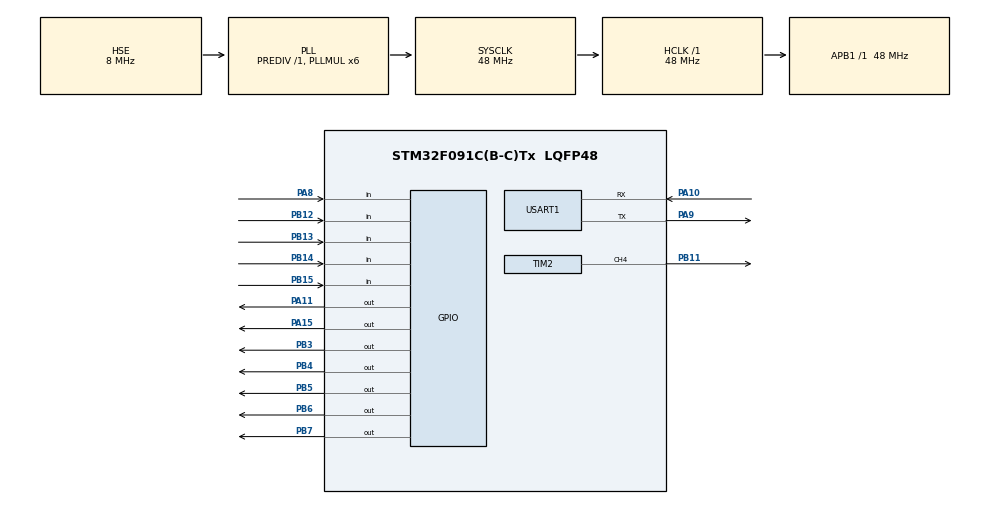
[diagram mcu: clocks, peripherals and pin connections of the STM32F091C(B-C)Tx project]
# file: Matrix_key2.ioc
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Dma.Request0=TIM2_CH4
Dma.TIM2_CH4.0.Direction=DMA_MEMORY_TO_PERIPH
Dma.TIM2_CH4.0.Instance=DMA1_Channel4
Dma.TIM2_CH4.0.MemDataAlignment=DMA_MDATAALIGN_WORD
Dma.TIM2_CH4.0.MemInc=DMA_MINC_ENABLE
Dma.TIM2_CH4.0.Mode=DMA_NORMAL
Dma.TIM2_CH4.0.PeriphDataAlignment=DMA_PDATAALIGN_WORD
Dma.TIM2_CH4.0.PeriphInc=DMA_PINC_DISABLE
Dma.TIM2_CH4.0.Priority=DMA_PRIORITY_LOW
Mcu.Family=STM32F0
Mcu.Name=STM32F091C(B-C)Tx
Mcu.Package=LQFP48
NVIC.DMA1_Ch4_7_DMA2_Ch3_5_IRQn=true\:0\:0\:false\:false\:true\:false\:true\:true
NVIC.TIM3_IRQn=true\:0\:0\:false\:false\:true\:true\:true\:true
NVIC.TIM7_IRQn=true\:0\:0\:false\:false\:true\:true\:true\:true
PA10.Mode=Asynchronous
PA10.Signal=USART1_RX
PA11.GPIO_PuPd=GPIO_PULLUP
PA11.Signal=GPIO_Output
PA13.Mode=Serial_Wire
PA13.Signal=SYS_SWDIO
PA14.Mode=Serial_Wire
PA14.Signal=SYS_SWCLK
PA15.GPIO_PuPd=GPIO_PULLUP
PA15.GPIO_Speed=GPIO_SPEED_FREQ_HIGH
PA15.Signal=GPIO_Output
PA8.GPIO_PuPd=GPIO_PULLUP
PA8.Signal=GPIO_Input
PA9.Mode=Asynchronous
PA9.Signal=USART1_TX
PB11.Signal=S_TIM2_CH4
PB12.GPIO_PuPd=GPIO_PULLUP
PB12.Signal=GPIO_Input
PB13.GPIO_PuPd=GPIO_PULLUP
PB13.Signal=GPIO_Input
PB14.GPIO_PuPd=GPIO_PULLUP
PB14.Signal=GPIO_Input
PB15.GPIO_PuPd=GPIO_PULLUP
PB15.Signal=GPIO_Input
PB3.GPIO_PuPd=GPIO_PULLUP
PB3.Signal=GPIO_Output
PB4.GPIO_PuPd=GPIO_PULLUP
PB4.Signal=GPIO_Output
PB5.GPIO_PuPd=GPIO_PULLUP
PB5.Signal=GPIO_Output
PB6.GPIO_PuPd=GPIO_PULLUP
PB6.Signal=GPIO_Output
PB7.GPIO_PuPd=GPIO_PULLUP
PB7.Signal=GPIO_Output
PF0-OSC_IN.Mode=HSE-External-Oscillator
PF0-OSC_IN.Signal=RCC_OSC_IN
PF1-OSC_OUT.Mode=HSE-External-Oscillator
PF1-OSC_OUT.Signal=RCC_OSC_OUT
PF11BOOT0.GPIO_PuPd=GPIO_PULLUP
PF11BOOT0.Signal=GPIO_Output
ProjectManager.HeapSize=0x200
ProjectManager.StackSize=0x400
ProjectManager.TargetToolchain=STM32CubeIDE
RCC.AHBFreq_Value=48000000
RCC.APB1Freq_Value=48000000
RCC.APB1TimFreq_Value=48000000
RCC.HCLKFreq_Value=48000000
RCC.PLLMUL=RCC_PLL_MUL6
RCC.PLLSourceVirtual=RCC_PLLSOURCE_HSE
RCC.SYSCLKFreq_VALUE=48000000
RCC.SYSCLKSource=RCC_SYSCLKSOURCE_PLLCLK
SH.S_TIM2_CH4.0=TIM2_CH4,PWM Generation4 CH4
TIM2.Channel-PWM\ Generation4\ CH4=TIM_CHANNEL_4
TIM2.Period=59
TIM2.Pulse-PWM\ Generation4\ CH4=0
TIM3.AutoReloadPreload=TIM_AUTORELOAD_PRELOAD_DISABLE
TIM3.Period=1000
TIM3.Prescaler=479
TIM7.Period=500
TIM7.Prescaler=48000
USART1.VirtualMode-Asynchronous=VM_ASYNC
VP_TIM2_VS_ClockSourceINT.Mode=Internal
VP_TIM3_VS_ClockSourceINT.Mode=Internal
VP_TIM7_VS_ClockSourceINT.Mode=Enable_Timer
board=custom

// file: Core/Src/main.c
/* USER CODE BEGIN Header */
/**
  ******************************************************************************
  * @file           : main.c
  * @brief          : Main program body
  ******************************************************************************
  * @attention
  *
  * Copyright (c) 2023 STMicroelectronics.
  * All rights reserved.
  *
  * This software is licensed under terms that can be found in the LICENSE file
  * in the root directory of this software component.
  * If no LICENSE file comes with this software, it is provided AS-IS.
  *
  ******************************************************************************
  */
/* USER CODE END Header */
#include "main.h"
#include "dma.h"
#include "tim.h"
#include "usart.h"
#include "gpio.h"

/* USER CODE BEGIN Includes */
#include "string.h"
#include "stdio.h"
#include "stdbool.h"
#include <stdlib.h>
#include <stdint.h>
//#include "ws2812/ws2812.h"
//#include  "Button/Button.h"
/* USER CODE END Includes */

/* USER CODE BEGIN PD */

//#define COL_COUNT	8

/* USER CODE END PD */

/* USER CODE BEGIN PM */
/*
#define M_COL_A	(GPIOF->BSRR|=GPIO_BSRR_BR_11, GPIOB->BSRR|=GPIO_BSRR_BS_7|GPIO_BSRR_BS_6|GPIO_BSRR_BS_5|GPIO_BSRR_BS_4|GPIO_BSRR_BS_3, GPIOA->BSRR|=GPIO_BSRR_BS_15|GPIO_BSRR_BS_11)
#define M_COL_B	(GPIOF->BSRR|=GPIO_BSRR_BS_11, GPIOB->BSRR|=GPIO_BSRR_BR_7|GPIO_BSRR_BS_6|GPIO_BSRR_BS_5|GPIO_BSRR_BS_4|GPIO_BSRR_BS_3, GPIOA->BSRR|=GPIO_BSRR_BS_15|GPIO_BSRR_BS_11)
#define M_COL_C	(GPIOF->BSRR|=GPIO_BSRR_BS_11, GPIOB->BSRR|=GPIO_BSRR_BS_7|GPIO_BSRR_BR_6|GPIO_BSRR_BS_5|GPIO_BSRR_BS_4|GPIO_BSRR_BS_3, GPIOA->BSRR|=GPIO_BSRR_BS_15|GPIO_BSRR_BS_11)
#define M_COL_D	(GPIOF->BSRR|=GPIO_BSRR_BS_11, GPIOB->BSRR|=GPIO_BSRR_BS_7|GPIO_BSRR_BS_6|GPIO_BSRR_BR_5|GPIO_BSRR_BS_4|GPIO_BSRR_BS_3, GPIOA->BSRR|=GPIO_BSRR_BS_15|GPIO_BSRR_BS_11)
#define M_COL_E	(GPIOF->BSRR|=GPIO_BSRR_BS_11, GPIOB->BSRR|=GPIO_BSRR_BS_7|GPIO_BSRR_BS_6|GPIO_BSRR_BS_5|GPIO_BSRR_BR_4|GPIO_BSRR_BS_3, GPIOA->BSRR|=GPIO_BSRR_BS_15|GPIO_BSRR_BS_11)
#define M_COL_F	(GPIOF->BSRR|=GPIO_BSRR_BS_11, GPIOB->BSRR|=GPIO_BSRR_BS_7|GPIO_BSRR_BS_6|GPIO_BSRR_BS_5|GPIO_BSRR_BS_4|GPIO_BSRR_BR_3, GPIOA->BSRR|=GPIO_BSRR_BS_15|GPIO_BSRR_BS_11)
#define M_COL_G	(GPIOF->BSRR|=GPIO_BSRR_BS_11, GPIOB->BSRR|=GPIO_BSRR_BS_7|GPIO_BSRR_BS_6|GPIO_BSRR_BS_5|GPIO_BSRR_BS_4|GPIO_BSRR_BS_3, GPIOA->BSRR|=GPIO_BSRR_BR_15|GPIO_BSRR_BS_11)
#define M_COL_DP	(GPIOF->BSRR|=GPIO_BSRR_BS_11, GPIOB->BSRR|=GPIO_BSRR_BS_7|GPIO_BSRR_BS_6|GPIO_BSRR_BS_5|GPIO_BSRR_BS_4|GPIO_BSRR_BS_3, GPIOA->BSRR|=GPIO_BSRR_BS_15|GPIO_BSRR_BR_11)
*/
/* USER CODE END PM */

/* USER CODE BEGIN PV */
/*
uint8_t col_numb = 0;
uint8_t row_numb = 0;
uint8_t st_kbd = 0;
uint8_t cnt_tick = 10;
uint8_t row_data = 0xFF;
uint8_t but_status;
bool b_butpres;
bool b_enprint;
uint8_t cnt_scan = 0;
uint8_t n_col = 0;
uint8_t n_row = 0;
char test1[64];
uint8_t key[5][8] = {{1,2,3,4,5,6,7,8},
				  {9,10,11,12,13,14,15,16},
				  {17,18,19,20,21,22,23,24},
				  {25,26,27,28,29,30,31,32},
				  {33,34,35,36,37,38,39,40}};

extern uint32_t BUF_DMA [ARRAY_LEN];
uint16_t position_ws=0;
bool led_stat;
*/
/* USER CODE END PV */

void SystemClock_Config(void);

/* USER CODE BEGIN 0 */
/*
void HAL_TIM_PeriodElapsedCallback(TIM_HandleTypeDef *htim){
		if(htim -> Instance == TIM3){

			keyboard.COL_SCAN();
			keyboard.ROW_SCAN();
		}

		if(htim->Instance == TIM7){

		}
	}
*/
/* USER CODE END 0 */

int main(void)
{

  /* MCU Configuration--------------------------------------------------------*/

  /* Reset of all peripherals, Initializes the Flash interface and the Systick. */
  HAL_Init();

  /* Configure the system clock */
  SystemClock_Config();

  /* Initialize all configured peripherals */
  MX_GPIO_Init();
  MX_DMA_Init();
  MX_TIM3_Init();
  MX_USART1_UART_Init();
  MX_TIM2_Init();
  MX_TIM7_Init();
  /* USER CODE BEGIN 2 */
  HAL_TIM_Base_Start_IT(&htim3);
  HAL_TIM_Base_Start_IT(&htim7);
//  BUF_DMA[0] = 19;
 // HAL_TIM_PWM_Start(&htim2, TIM_CHANNEL_4);
 // HAL_TIM_PWM_Start_DMA(&htim2,TIM_CHANNEL_4,(uint32_t*)&BUF_DMA,1);
//  ws2812_init();
 // ws2812_pixel_rgb_to_buf_dma(0, 128, 128, 2);

 // HAL_TIM_PWM_Start_DMA(&htim2,TIM_CHANNEL_4,(uint32_t*)&BUF_DMA,2);
  /* USER CODE END 2 */

  /* Infinite loop */
  /* USER CODE BEGIN WHILE */
  while (1)
  {
	  CppMain();
	  //для индикации только во время нажатия
	/*  if(b_butpres == true){
		  	position_ws = ws_num_led(n_row, n_col);
		    ws2812_init();
		  ws2812_pixel_rgb_to_buf_dma(0, 128, 128, position_ws);
		  HAL_TIM_PWM_Start_DMA(&htim2,TIM_CHANNEL_4,(uint32_t*)&BUF_DMA,ARRAY_LEN);
		  	  b_butpres = false;
	  } if(but_status == 0){
		  ws2812_init();
		  HAL_TIM_PWM_Start_DMA(&htim2,TIM_CHANNEL_4,(uint32_t*)&BUF_DMA,ARRAY_LEN);
	  }
*/
/*
	  if(but_status == 0){
		  ws2812_init();
		  HAL_TIM_PWM_Start_DMA(&htim2,TIM_CHANNEL_4,(uint32_t*)&BUF_DMA,ARRAY_LEN);
	  }
*/
/*
	  if(b_enprint == true){
		  sprintf(test1, "%d\r\n",key[n_row][n_col]);
		  	position_ws = ws_num_led(n_row, n_col);		//для индикации нажатия
		    ws2812_init();
		  ws2812_pixel_rgb_to_buf_dma(0, 128, 128, position_ws);
		  HAL_TIM_PWM_Start_DMA(&htim2,TIM_CHANNEL_4,(uint32_t*)&BUF_DMA,ARRAY_LEN);
		  HAL_UART_Transmit(&huart1, (uint8_t*)&test1, strlen(test1), 100);
		  b_enprint = false;
	  }
*/
    /* USER CODE END WHILE */

  }
}

void SystemClock_Config(void)
{
  RCC_OscInitTypeDef RCC_OscInitStruct = {0};
  RCC_ClkInitTypeDef RCC_ClkInitStruct = {0};
  RCC_PeriphCLKInitTypeDef PeriphClkInit = {0};

  /** Initializes the RCC Oscillators according to the specified parameters
  * in the RCC_OscInitTypeDef structure.
  */
  RCC_OscInitStruct.OscillatorType = RCC_OSCILLATORTYPE_HSE;
  RCC_OscInitStruct.HSEState = RCC_HSE_ON;
  RCC_OscInitStruct.PLL.PLLState = RCC_PLL_ON;
  RCC_OscInitStruct.PLL.PLLSource = RCC_PLLSOURCE_HSE;
  RCC_OscInitStruct.PLL.PLLMUL = RCC_PLL_MUL6;
  RCC_OscInitStruct.PLL.PREDIV = RCC_PREDIV_DIV1;
  if (HAL_RCC_OscConfig(&RCC_OscInitStruct) != HAL_OK)
  {
    Error_Handler();
  }

  /** Initializes the CPU, AHB and APB buses clocks
  */
  RCC_ClkInitStruct.ClockType = RCC_CLOCKTYPE_HCLK|RCC_CLOCKTYPE_SYSCLK
                              |RCC_CLOCKTYPE_PCLK1;
  RCC_ClkInitStruct.SYSCLKSource = RCC_SYSCLKSOURCE_PLLCLK;
  RCC_ClkInitStruct.AHBCLKDivider = RCC_SYSCLK_DIV1;
  RCC_ClkInitStruct.APB1CLKDivider = RCC_HCLK_DIV1;

  if (HAL_RCC_ClockConfig(&RCC_ClkInitStruct, FLASH_LATENCY_1) != HAL_OK)
  {
    Error_Handler();
  }
  PeriphClkInit.PeriphClockSelection = RCC_PERIPHCLK_USART1;
  PeriphClkInit.Usart1ClockSelection = RCC_USART1CLKSOURCE_PCLK1;
  if (HAL_RCCEx_PeriphCLKConfig(&PeriphClkInit) != HAL_OK)
  {
    Error_Handler();
  }
}

void Error_Handler(void)
{
  __disable_irq();
  while (1)
  {
  }
}
